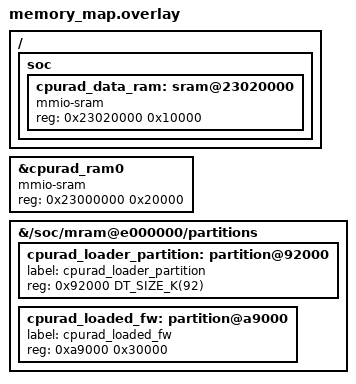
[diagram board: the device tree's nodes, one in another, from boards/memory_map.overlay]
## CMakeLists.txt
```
# SPDX-License-Identifier: Apache-2.0

cmake_minimum_required(VERSION 3.20.0)
find_package(Zephyr REQUIRED HINTS $ENV{ZEPHYR_BASE})
project(ibeacon)

target_sources(app PRIVATE src/main.c)

if(IBEACON_RSSI)
  zephyr_compile_definitions(IBEACON_RSSI=${IBEACON_RSSI})
endif()

target_include_directories(app PRIVATE ../../../../../samples/radio_loader/shared_magic)
```

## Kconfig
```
#
# Copyright (c) 2023 Nordic Semiconductor ASA
#
# SPDX-License-Identifier: LicenseRef-Nordic-5-Clause
#

source "Kconfig.zephyr"

choice RADIO_LOADER_MODE
	prompt "Radio loader mode"
	default RADIO_LOADER_MODE_COPY

config RADIO_LOADER_MODE_COPY
	bool "Copy mode - don't do anything in app core image"

config RADIO_LOADER_MODE_MPC
	bool "MPC mode - copy firmware to TCM from app core while radio loader configures access and jumps to it"

endchoice
```

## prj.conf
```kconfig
CONFIG_BT=y
CONFIG_BT_PERIPHERAL=y
CONFIG_BT_CENTRAL=n
CONFIG_BT_DEVICE_NAME="Nordic_HRS"
CONFIG_BT_BAS=y
CONFIG_BT_HRS=y
CONFIG_BT_CTLR_PHY_CODED=y
CONFIG_BT_CTLR_ADV_EXT=y
CONFIG_BT_EXT_ADV=y
CONFIG_BT_EXT_ADV_CODING_SELECTION=y
CONFIG_BT_USER_PHY_UPDATE=y


CONFIG_LOG=y
# CONFIG_CONSOLE=n
# CONFIG_UART_CONSOLE=n
# CONFIG_SERIAL=n
# CONFIG_LOG=n

CONFIG_SOC_NRF54H20_CPURAD_ENABLE=y

CONFIG_RADIO_LOADER_MODE_COPY=y

CONFIG_PM=y
CONFIG_PM_DEVICE=y
CONFIG_PM_DEVICE_RUNTIME=y
CONFIG_PM_S2RAM=y
CONFIG_PM_S2RAM_CUSTOM_MARKING=y

CONFIG_DK_LIBRARY=y
```

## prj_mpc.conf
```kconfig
# # CONFIG_BT=y
# # CONFIG_BT_PERIPHERAL=y
# # CONFIG_BT_DEVICE_NAME="Nordic_HRS"
# # CONFIG_BT_BAS=y
# # CONFIG_BT_HRS=y
# # CONFIG_BT_CTLR_PHY_CODED=y
# # CONFIG_BT_CTLR_ADV_EXT=y
# # CONFIG_BT_EXT_ADV=y
# # CONFIG_BT_EXT_ADV_CODING_SELECTION=y
# # CONFIG_BT_USER_PHY_UPDATE=y


# # CONFIG_LOG=y
# CONFIG_CONSOLE=n
# CONFIG_UART_CONSOLE=n
# CONFIG_SERIAL=n
# CONFIG_LOG=n

# CONFIG_SOC_NRF54H20_CPURAD_ENABLE=y

# CONFIG_RADIO_LOADER_MODE_MPC=y

# CONFIG_PM=y
# CONFIG_PM_DEVICE=y
# CONFIG_PM_DEVICE_RUNTIME=y
# CONFIG_PM_S2RAM=y
# CONFIG_PM_S2RAM_CUSTOM_MARKING=y

# # CONFIG_DK_LIBRARY=y



# #############################

# CONFIG_NCS_SAMPLES_DEFAULTS=y
# CONFIG_DK_LIBRARY=y

# CONFIG_BT=y
# CONFIG_BT_PERIPHERAL=y
# CONFIG_BT_DEVICE_NAME="Nordic_HRS"
# CONFIG_BT_BAS=y
# CONFIG_BT_HRS=y

# CONFIG_BT_CTLR_PHY_CODED=y
# CONFIG_BT_CTLR_ADV_EXT=y

# CONFIG_BT_EXT_ADV=y
# CONFIG_BT_EXT_ADV_CODING_SELECTION=y
# CONFIG_BT_USER_PHY_UPDATE=y

CONFIG_BT=y
CONFIG_BT_PERIPHERAL=y
CONFIG_BT_CENTRAL=n
CONFIG_BT_DEVICE_NAME="Nordic_HRS"
CONFIG_BT_BAS=y
CONFIG_BT_HRS=y
CONFIG_BT_CTLR_PHY_CODED=y
CONFIG_BT_CTLR_ADV_EXT=y
CONFIG_BT_EXT_ADV=y
CONFIG_BT_EXT_ADV_CODING_SELECTION=y
CONFIG_BT_USER_PHY_UPDATE=y


# CONFIG_LOG=y
CONFIG_CONSOLE=n
CONFIG_UART_CONSOLE=n
CONFIG_SERIAL=n
CONFIG_LOG=n

CONFIG_SOC_NRF54H20_CPURAD_ENABLE=y

CONFIG_RADIO_LOADER_MODE_MPC=y

CONFIG_PM=y
CONFIG_PM_DEVICE=y
CONFIG_PM_DEVICE_RUNTIME=y
CONFIG_PM_S2RAM=y
CONFIG_PM_S2RAM_CUSTOM_MARKING=y

CONFIG_DK_LIBRARY=y
```

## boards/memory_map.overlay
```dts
/*
 * Copyright (c) 2025 Nordic Semiconductor ASA
 *
 * SPDX-License-Identifier: LicenseRef-Nordic-5-Clause
 */

/*
 * Common memory map configuration for cpurad
 * Shared between remote firmware and radio_loader
 */

/{
	soc{
		cpurad_data_ram: sram@23020000 {
			compatible = "mmio-sram";
			reg = < 0x23020000 0x10000 >;
			#address-cells = < 0x1 >;
			#size-cells = < 0x1 >;
			ranges = < 0x0 0x23020000 0x10000 >;
		};

		// cpurad_data_ram: sram@2f029000 {
		// 	compatible = "mmio-sram";
		// 	reg = < 0x2f029000 0x10000 >;
		// 	#address-cells = < 0x1 >;
		// 	#size-cells = < 0x1 >;
		// 	ranges = < 0x0 0x2f029000 0x10000 >;
		// };
	};
};

&cpurad_ram0 {
	compatible = "mmio-sram";
	/delete-property/ reg;
	reg = < 0x23000000 0x20000 >;
	ranges = < 0x0 0x23000000 0x20000 >;
};

// &cpurad_ram0 {
// 	compatible = "mmio-sram";
// 	/delete-property/ reg;
// 	reg = < 0x23000000 0x30000 >;
// 	ranges = < 0x0 0x23000000 0x30000 >;
// };

&{/soc/mram@e000000/partitions} {
	// Remove the old cpurad_slot0_partition definition
	/delete-node/ cpurad_slot0_partition;

	// Add new partition for loader
	cpurad_loader_partition: partition@92000 {
		label = "cpurad_loader_partition";
		reg = <0x92000 DT_SIZE_K(92)>;
	};

	// Add new partition for loaded firmware
	cpurad_loaded_fw: partition@a9000 {
		label = "cpurad_loaded_fw";
		// Size: 128KB (0x20000) for firmware image
		reg = <0xa9000 0x30000>;
	};
};
```

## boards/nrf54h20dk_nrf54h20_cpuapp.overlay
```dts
/*
 * Copyright (c) 2025 Nordic Semiconductor ASA
 *
 * SPDX-License-Identifier: LicenseRef-Nordic-5-Clause
 */

// &cpuapp_data {
// 	reg = <0x2f000000 0x39000>;
// };

&cpuapp_data {
	reg = <0x2f000000 0x29000>;
};
```

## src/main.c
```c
/*
 * Copyright (c) 2020 Nordic Semiconductor ASA
 *
 * SPDX-License-Identifier: LicenseRef-Nordic-5-Clause
 */

/** @file
 *  @brief Peripheral Heart Rate over LE Coded PHY sample
 */
#include <stddef.h>
#include <string.h>
#include <errno.h>
#include <zephyr/kernel.h>
#include <zephyr/types.h>
#include <zephyr/sys/printk.h>

#include <zephyr/bluetooth/bluetooth.h>
#include <zephyr/bluetooth/conn.h>
#include <zephyr/bluetooth/gatt.h>
#include <zephyr/bluetooth/hci.h>
#include <zephyr/bluetooth/uuid.h>
#include <zephyr/bluetooth/services/bas.h>
#include <zephyr/bluetooth/services/hrs.h>

#include <dk_buttons_and_leds.h>

#define DEVICE_NAME             CONFIG_BT_DEVICE_NAME
#define DEVICE_NAME_LEN         (sizeof(DEVICE_NAME) - 1)

#define RUN_STATUS_LED          DK_LED1
#define CON_STATUS_LED          DK_LED2
#define RUN_LED_BLINK_INTERVAL  1000
#define NOTIFY_INTERVAL         1000

static void start_advertising_coded(struct k_work *work);
static void notify_work_handler(struct k_work *work);

static K_WORK_DEFINE(start_advertising_worker, start_advertising_coded);
static K_WORK_DELAYABLE_DEFINE(notify_work, notify_work_handler);

static struct bt_le_ext_adv *adv;

static const struct bt_data ad[] = {
	BT_DATA_BYTES(BT_DATA_FLAGS, (BT_LE_AD_GENERAL | BT_LE_AD_NO_BREDR)),
	BT_DATA_BYTES(BT_DATA_UUID16_ALL, BT_UUID_16_ENCODE(BT_UUID_HRS_VAL),
					  BT_UUID_16_ENCODE(BT_UUID_BAS_VAL),
					  BT_UUID_16_ENCODE(BT_UUID_DIS_VAL)),
	BT_DATA(BT_DATA_NAME_COMPLETE, DEVICE_NAME, DEVICE_NAME_LEN)
};


#include "../../../../../samples/radio_loader/shared_magic/shared_magic.h"

#define LOADED_FW_ADDR        		0x0e0a9000
// #define LOADED_FW_SIZE        		0x30000
#define LOADED_FW_SIZE        		0x20000

#define LOADED_FW_RAM_ADDR    		0x23000000
// #define LOADED_FW_RAM_SIZE    		0x30000
#define LOADED_FW_RAM_SIZE    		0x20000

void radio_fw_copy(void)
{
	printk("Waiting for the MPC to be configured.\n");
	/* Wait for the MPC to be configured. */
	shared_magic_wait_for_mpc_ready();
	printk("MPC is configured.\n");

	/* Consume the magic. */
	shared_magic_consume();

	//todo: check which cache ops are needed and where
	sys_cache_data_flush_and_invd_all();

	/* Copy the firmware to the TCM. */
	memcpy((void *)LOADED_FW_RAM_ADDR, (void *)LOADED_FW_ADDR, LOADED_FW_SIZE);
	printk("Copied the firmware to the TCM.\n");

	//todo: check which cache ops are needed and where
	sys_cache_data_flush_and_invd_all();

	/* Set the magic to the boot ready magic. */
	shared_magic_set_boot_ready();
	printk("Magic set to the boot ready magic.\n");
}

static const char *phy_to_str(uint8_t phy)
{
	switch (phy) {
	case BT_GAP_LE_PHY_NONE:
		return "No packets";
	case BT_GAP_LE_PHY_1M:
		return "LE 1M";
	case BT_GAP_LE_PHY_2M:
		return "LE 2M";
	case BT_GAP_LE_PHY_CODED:
		return "LE Coded";
	case BT_GAP_LE_PHY_CODED_S8:
		return "S=8 Coded";
	case BT_GAP_LE_PHY_CODED_S2:
		return "S=2 Coded";
	default: return "Unknown";
	}
}

static void connected(struct bt_conn *conn, uint8_t conn_err)
{
	int err;
	struct bt_conn_info info;
	char addr[BT_ADDR_LE_STR_LEN];

	bt_addr_le_to_str(bt_conn_get_dst(conn), addr, sizeof(addr));

	if (conn_err) {
		printk("Connection failed, err 0x%02x %s\n", conn_err, bt_hci_err_to_str(conn_err));
		return;
	}

	err = bt_conn_get_info(conn, &info);
	if (err) {
		printk("Failed to get connection info (err %d)\n", err);
	} else {
		const struct bt_conn_le_phy_info *phy_info;
		phy_info = info.le.phy;

		printk("Connected: %s, tx_phy %s, rx_phy %s\n",
		       addr, phy_to_str(phy_info->tx_phy), phy_to_str(phy_info->rx_phy));
	}

	dk_set_led_on(CON_STATUS_LED);
}

static void disconnected(struct bt_conn *conn, uint8_t reason)
{
	printk("Disconnected, reason 0x%02x %s\n", reason, bt_hci_err_to_str(reason));

	k_work_submit(&start_advertising_worker);

	dk_set_led_off(CON_STATUS_LED);
}

BT_CONN_CB_DEFINE(conn_callbacks) = {
	.connected = connected,
	.disconnected = disconnected,
};

static int create_advertising_coded(void)
{
	int err;
	struct bt_le_adv_param param =
		BT_LE_ADV_PARAM_INIT(BT_LE_ADV_OPT_CONN |
				     BT_LE_ADV_OPT_EXT_ADV |
				     BT_LE_ADV_OPT_CODED,
				     BT_GAP_ADV_FAST_INT_MIN_2,
				     BT_GAP_ADV_FAST_INT_MAX_2,
				     NULL);

	err = bt_le_ext_adv_create(&param, NULL, &adv);
	if (err) {
		printk("Failed to create advertiser set (err %d)\n", err);
		return err;
	}

	printk("Created adv: %p\n", adv);

	err = bt_le_ext_adv_set_data(adv, ad, ARRAY_SIZE(ad), NULL, 0);
	if (err) {
		printk("Failed to set advertising data (err %d)\n", err);
		return err;
	}

	return 0;
}

static void start_advertising_coded(struct k_work *work)
{
	int err;

	err = bt_le_ext_adv_start(adv, BT_LE_EXT_ADV_START_DEFAULT);
	if (err) {
		printk("Failed to start advertising set (err %d)\n", err);
		return;
	}

	printk("Advertiser %p set started\n", adv);
}

static void bas_notify(void)
{
	uint8_t battery_level = bt_bas_get_battery_level();

	__ASSERT_NO_MSG(battery_level > 0);

	battery_level--;

	if (!battery_level) {
		battery_level = 100;
	}

	bt_bas_set_battery_level(battery_level);
}

static void hrs_notify(void)
{
	static uint8_t heartrate = 100;

	heartrate++;
	if (heartrate == 160) {
		heartrate = 100;
	}

	bt_hrs_notify(heartrate);
}

static void notify_work_handler(struct k_work *work)
{
	/* Services data simulation. */
	hrs_notify();
	bas_notify();

	k_work_reschedule(k_work_delayable_from_work(work), K_MSEC(NOTIFY_INTERVAL));
}

int main(void)
{
	uint32_t led_status = 0;
	int err;

	uintptr_t pc;
	__asm__ volatile("adr %0, ." : "=r"(pc));
	printk("Current PC (program counter) address: 0x%lx\n", (unsigned long)pc);

	if (IS_ENABLED(CONFIG_RADIO_LOADER_MODE_MPC)) {
		radio_fw_copy();
	}

	printk("Starting Bluetooth Peripheral HR coded sample\n");

	err = dk_leds_init();
	if (err) {
		printk("LEDs init failed (err %d)\n", err);
		return 0;
	}

	err = bt_enable(NULL);
	if (err) {
		printk("Bluetooth init failed (err %d)\n", err);
		return 0;
	}

	printk("Bluetooth initialized\n");

	err = create_advertising_coded();
	if (err) {
		printk("Advertising failed to create (err %d)\n", err);
		return 0;
	}

	bt_addr_le_t addr;
	size_t count = 1;
	char addr_str[BT_ADDR_LE_STR_LEN];

	bt_id_get(&addr, &count);
	bt_addr_le_to_str(&addr, addr_str, sizeof(addr_str));
	printk("Advertising BLE address: %s\n", addr_str);

	k_work_submit(&start_advertising_worker);
	k_work_schedule(&notify_work, K_NO_WAIT);

	for (;;) {
		dk_set_led(RUN_STATUS_LED, (++led_status) % 2);
		k_sleep(K_MSEC(RUN_LED_BLINK_INTERVAL));
	}
}
```
